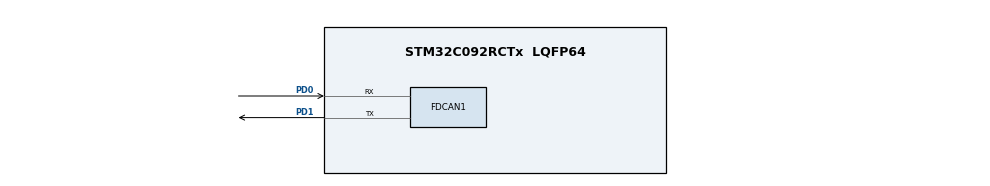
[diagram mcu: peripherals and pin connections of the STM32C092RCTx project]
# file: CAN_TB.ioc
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FDCAN1.CalculateBaudRateNominal=250000
FDCAN1.CalculateTimeBitNominal=4000
FDCAN1.CalculateTimeQuantumNominal=1333.3333333333333
Mcu.Family=STM32C0
Mcu.Name=STM32C092RCTx
Mcu.Package=LQFP64
NUCLEO-C092RC.BUTTON=1
NUCLEO-C092RC.LD1=true
NUCLEO-C092RC.LD2=true
NUCLEO-C092RC.VCP=true
NVIC.EXTI4_15_IRQn=true\:0\:0\:false\:false\:true\:false\:true\:true
PA13.GPIO_Label=SWDIO
PA13.Signal=DEBUG_SWDIO
PA14-BOOT0.GPIO_Label=SWCLK
PA14-BOOT0.Signal=DEBUG_SWCLK
PA2.Signal=USART2_TX
PA3.Signal=USART2_RX
PC14-OSCX_IN(PC14).GPIO_Label=OSCX_IN
PC14-OSCX_IN(PC14).Signal=RCC_OSCX_IN
PC15-OSCX_OUT(PC15).GPIO_Label=OSCX_OUT
PC15-OSCX_OUT(PC15).Signal=RCC_OSCX_OUT
PD0.Mode=FDCAN_Activate
PD0.Signal=FDCAN1_RX
PD1.Mode=FDCAN_Activate
PD1.Signal=FDCAN1_TX
PF0-OSC_IN(PF0).GPIO_Label=OSC_IN
PF0-OSC_IN(PF0).Signal=RCC_OSC_IN
PF1-OSC_OUT(PF1).GPIO_Label=OSC_OUT
PF1-OSC_OUT(PF1).Signal=RCC_OSC_OUT
ProjectManager.HeapSize=0x200
ProjectManager.StackSize=0x400
ProjectManager.TargetToolchain=Makefile
RCC.ADCFreq_Value=12000000
RCC.AHBFreq_Value=12000000
RCC.CortexFreq_Value=12000000
RCC.EXTERNAL_CLOCK_VALUE=12288000
RCC.HCLKFreq_Value=12000000
RCC.HSE_VALUE=8000000
RCC.HSI_VALUE=48000000
RCC.LSE_VALUE=32768
RCC.SYSCLKFreq_VALUE=12000000
VP_NUCLEO-C092RC_VS_BSP_COMMON.Mode=COMMON
board=NUCLEO-C092RC

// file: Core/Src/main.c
/* USER CODE BEGIN Header */
/**
  ******************************************************************************
  * @file           : main.c
  * @brief          : Main program body
  ******************************************************************************
  * @attention
  *
  * Copyright (c) 2026 STMicroelectronics.
  * All rights reserved.
  *
  * This software is licensed under terms that can be found in the LICENSE file
  * in the root directory of this software component.
  * If no LICENSE file comes with this software, it is provided AS-IS.
  *
  ******************************************************************************
  */
/* USER CODE END Header */
#include "main.h"

/* USER CODE BEGIN Includes */
#include "CANSIM.h"
#include "CANParser.h"
#include "our_candata.h"
#include "stm32c0xx.h"
/* USER CODE END Includes */

/* USER CODE BEGIN PD */
#define TX_INTERVAL_MS  10u
/* USER CODE END PD */

COM_InitTypeDef BspCOMInit;

FDCAN_HandleTypeDef hfdcan1;

/* USER CODE BEGIN PV */
static CAN_SimHandle  sim;
static our_candata    candata = {0};
static uint32_t       last_tx_tick = 0;
/* USER CODE END PV */

void SystemClock_Config(void);
static void MX_GPIO_Init(void);
static void MX_FDCAN1_Init(void);

int main(void)
{

  /* USER CODE BEGIN 1 */
// // Blink immediately using raw register access, no HAL needed
  RCC->IOPENR |= RCC_IOPENR_GPIOAEN;  // enable GPIOA clock
  GPIOA->MODER &= ~(3u << (5*2));
  GPIOA->MODER |=  (1u << (5*2));      // PA5 as output (green LED on Nucleo)
//     for (int i = 0; i < 10; i++) {
//         GPIOA->ODR ^= (1u << 5);
//         for (volatile int d = 0; d < 100000; d++);
//     }
    #define CHECKPOINT() do { \
        for (int i = 0; i < 3; i++) { \
            GPIOA->ODR ^= (1u << 5); \
            for (volatile int d = 0; d < 200000; d++); \
        } \
    } while(0)
  /* USER CODE END 1 */

  /* MCU Configuration--------------------------------------------------------*/

  /* Reset of all peripherals, Initializes the Flash interface and the Systick. */
  HAL_Init();

          // 3 blinks = got past HAL_Init

  /* Configure the system clock */
  SystemClock_Config();

  /* Initialize all configured peripherals */
  MX_GPIO_Init();

  MX_FDCAN1_Init();

  /* Initialize leds */
  BSP_LED_Init(LED_GREEN);
  BSP_LED_Init(LED_BLUE);

  /* Initialize USER push-button, will be used to trigger an interrupt each time it's pressed.*/
  BSP_PB_Init(BUTTON_USER, BUTTON_MODE_EXTI);

  /* USER CODE BEGIN 2 */
  HAL_FDCAN_Start(&hfdcan1);

  HAL_FDCAN_ActivateNotification(
    &hfdcan1,
    FDCAN_IT_RX_FIFO0_NEW_MESSAGE,
    0
  );

  CAN_SimConfig cfg = {
    .base_id    = 0x100,
    .mode       = CAN_MODE_RAMP,
    .bytes      = 8,
    .use_ext_id = false
};

  CAN_Sim_Init(&sim, cfg);

  /* USER CODE END 2 */

  /* Initialize COM1 port (115200, 8 bits (7-bit data + 1 stop bit), no parity */
  BspCOMInit.BaudRate   = 115200;
  BspCOMInit.WordLength = COM_WORDLENGTH_8B;
  BspCOMInit.StopBits   = COM_STOPBITS_1;
  BspCOMInit.Parity     = COM_PARITY_NONE;
  BspCOMInit.HwFlowCtl  = COM_HWCONTROL_NONE;
  if (BSP_COM_Init(COM1, &BspCOMInit) != BSP_ERROR_NONE)
  {
    Error_Handler();
  }

  /* Infinite loop */
/* USER CODE BEGIN WHILE */
  while (1)
  {

      if ((HAL_GetTick() - last_tx_tick) >= TX_INTERVAL_MS)
      {
          bool sent = CAN_Sim_Send(&sim, &hfdcan1);
          if (sent)
          {
              BSP_LED_Toggle(LED_GREEN);
              last_tx_tick = HAL_GetTick();
          }
          else
          {
              BSP_LED_Toggle(LED_BLUE);
          }
      }
      /* USER CODE END WHILE */

  }
}

void SystemClock_Config(void)
{
  RCC_OscInitTypeDef RCC_OscInitStruct = {0};
  RCC_ClkInitTypeDef RCC_ClkInitStruct = {0};

  __HAL_FLASH_SET_LATENCY(FLASH_LATENCY_0);

  /** Initializes the RCC Oscillators according to the specified parameters
  * in the RCC_OscInitTypeDef structure.
  */
  RCC_OscInitStruct.OscillatorType = RCC_OSCILLATORTYPE_HSI;
  RCC_OscInitStruct.HSIState = RCC_HSI_ON;
  RCC_OscInitStruct.HSIDiv = RCC_HSI_DIV4;
  RCC_OscInitStruct.HSICalibrationValue = RCC_HSICALIBRATION_DEFAULT;
  if (HAL_RCC_OscConfig(&RCC_OscInitStruct) != HAL_OK)
  {
    Error_Handler();
  }

  /** Initializes the CPU, AHB and APB buses clocks
  */
  RCC_ClkInitStruct.ClockType = RCC_CLOCKTYPE_HCLK|RCC_CLOCKTYPE_SYSCLK
                              |RCC_CLOCKTYPE_PCLK1;
  RCC_ClkInitStruct.SYSCLKSource = RCC_SYSCLKSOURCE_HSI;
  RCC_ClkInitStruct.SYSCLKDivider = RCC_SYSCLK_DIV1;
  RCC_ClkInitStruct.AHBCLKDivider = RCC_HCLK_DIV1;
  RCC_ClkInitStruct.APB1CLKDivider = RCC_APB1_DIV1;

  if (HAL_RCC_ClockConfig(&RCC_ClkInitStruct, FLASH_LATENCY_0) != HAL_OK)
  {
    Error_Handler();
  }
}

static void MX_FDCAN1_Init(void)
{

  hfdcan1.Instance = FDCAN1;
  hfdcan1.Init.ClockDivider = FDCAN_CLOCK_DIV1;
  hfdcan1.Init.FrameFormat = FDCAN_FRAME_CLASSIC;
  hfdcan1.Init.Mode = FDCAN_MODE_NORMAL;
  hfdcan1.Init.AutoRetransmission = ENABLE;
  hfdcan1.Init.TransmitPause = DISABLE;
  hfdcan1.Init.ProtocolException = DISABLE;
  // hfdcan1.Init.NominalPrescaler = 16;
  // hfdcan1.Init.NominalSyncJumpWidth = 1;
  // hfdcan1.Init.NominalTimeSeg1 = 1;
  // hfdcan1.Init.NominalTimeSeg2 = 1;
  //  hfdcan1.Init.StdFiltersNbr = 0;
  //um claude told me this just isnt the right clock settings so im gonna try it and see whats up
  hfdcan1.Init.NominalPrescaler     = 1;
  hfdcan1.Init.NominalSyncJumpWidth = 1;
  hfdcan1.Init.NominalTimeSeg1      = 21;
  hfdcan1.Init.NominalTimeSeg2      = 2;
  hfdcan1.Init.StdFiltersNbr = 1;
  hfdcan1.Init.DataPrescaler = 1;
  hfdcan1.Init.DataSyncJumpWidth = 1;
  hfdcan1.Init.DataTimeSeg1 = 1;
  hfdcan1.Init.DataTimeSeg2 = 1;

  hfdcan1.Init.ExtFiltersNbr = 0;
  hfdcan1.Init.TxFifoQueueMode = FDCAN_TX_FIFO_OPERATION;
  if (HAL_FDCAN_Init(&hfdcan1) != HAL_OK)
  {
    Error_Handler();
  }
  /* USER CODE BEGIN FDCAN1_Init 2 */
  FDCAN_FilterTypeDef filter = {
      .IdType       = FDCAN_STANDARD_ID,
      .FilterIndex  = 0,
      .FilterType   = FDCAN_FILTER_MASK,
      .FilterConfig = FDCAN_FILTER_TO_RXFIFO0,
      .FilterID1    = 0x000,
      .FilterID2    = 0x000
  };
  if (HAL_FDCAN_ConfigFilter(&hfdcan1, &filter) != HAL_OK)
  {
      Error_Handler();
  }
  /* USER CODE END FDCAN1_Init 2 */

}

static void MX_GPIO_Init(void)
{

  /* GPIO Ports Clock Enable */
  __HAL_RCC_GPIOC_CLK_ENABLE();
  __HAL_RCC_GPIOF_CLK_ENABLE();
  __HAL_RCC_GPIOA_CLK_ENABLE();
  __HAL_RCC_GPIOD_CLK_ENABLE();

  /* USER CODE BEGIN MX_GPIO_Init_2 */
  GPIO_InitTypeDef GPIO_InitStruct = {0};

  GPIO_InitStruct.Pin  = BUTTON_USER_PIN;
  GPIO_InitStruct.Mode = GPIO_MODE_IT_RISING;
  GPIO_InitStruct.Pull = GPIO_NOPULL;
  HAL_GPIO_Init(BUTTON_USER_GPIO_PORT, &GPIO_InitStruct);

  HAL_NVIC_SetPriority(BUTTON_USER_EXTI_IRQn, 1, 0);
  HAL_NVIC_EnableIRQ(BUTTON_USER_EXTI_IRQn);
  /* USER CODE END MX_GPIO_Init_2 */
}

/* USER CODE BEGIN 4 */
void HAL_FDCAN_RxFifo0Callback(FDCAN_HandleTypeDef *hfdcan, uint32_t RxFifo0ITs)
{
    FDCAN_RxHeaderTypeDef rxhdr;
    uint8_t data[8] = {0};

    if (HAL_FDCAN_GetRxMessage(hfdcan, FDCAN_RX_FIFO0, &rxhdr, data) == HAL_OK)
    {
        CAN_Dispatch(rxhdr.Identifier, data, &candata);
    }
}

void BSP_PB_Callback(Button_TypeDef Button)
{
    if (Button == BUTTON_USER)
    {
        CAN_SimMode next = (CAN_SimMode)((sim.cfg.mode + 1) % CAN_MODE_COUNT);
        CAN_Sim_SetMode(&sim, next);
    }
}
/* USER CODE END 4 */

  void Error_Handler(void)
{
    while (1)
    {
        BSP_LED_Toggle(LED_BLUE);
        HAL_Delay(200);
    }
}
// void Error_Handler(void)
// {
//   /* USER CODE BEGIN Error_Handler_Debug */
//   /* User can add his own implementation to report the HAL error return state */
//   __disable_irq();
//   while (1)
//   {
//   }
//   /* USER CODE END Error_Handler_Debug */
// }
